AUTOSAR XML (schema 314)
package /ComponentType
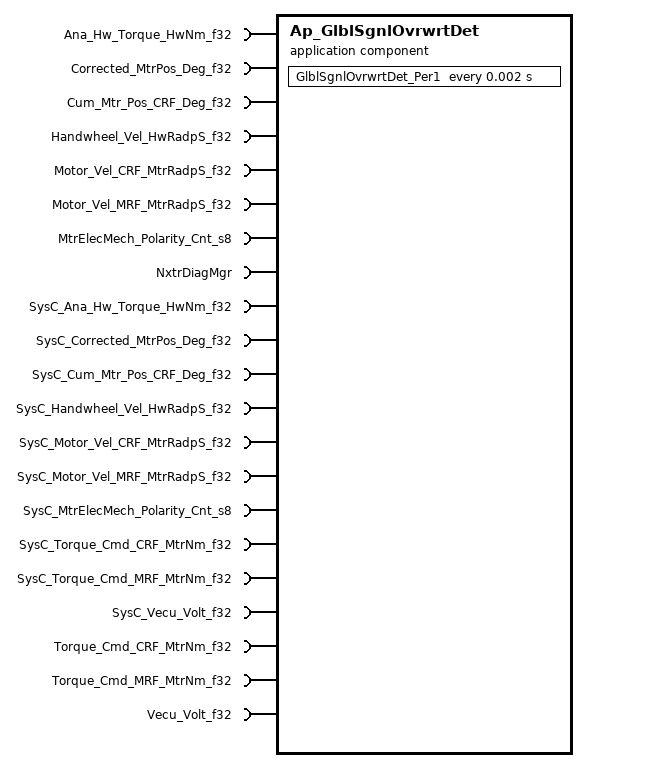
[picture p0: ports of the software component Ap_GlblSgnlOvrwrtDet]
  application software component type Ap_GlblSgnlOvrwrtDet
    21 x require port:
      Ana_Hw_Torque_HwNm_f32: unqueued-receiver-com-spec{data-element=HwNm_f32, init-value=D_ZERO_ULS_F32}, required-interface=Ana_Hw_Torque_HwNm_f32
      Corrected_MtrPos_Deg_f32: unqueued-receiver-com-spec{data-element=Deg_f32, init-value=D_ZERO_ULS_F32}, required-interface=Corrected_MtrPos_Deg_f32
      Cum_Mtr_Pos_CRF_Deg_f32: unqueued-receiver-com-spec{data-element=Deg_f32, init-value=D_ZERO_ULS_F32}, required-interface=Cum_Mtr_Pos_CRF_Deg_f32
      Handwheel_Vel_HwRadpS_f32: unqueued-receiver-com-spec{data-element=HwRadpS_f32, init-value=D_ZERO_ULS_F32}, required-interface=Handwheel_Vel_HwRadpS_f32
      Motor_Vel_CRF_MtrRadpS_f32: unqueued-receiver-com-spec{data-element=MtrRadpS_f32, init-value=D_ZERO_ULS_F32}, required-interface=Motor_Vel_CRF_MtrRadpS_f32
      Motor_Vel_MRF_MtrRadpS_f32: unqueued-receiver-com-spec{data-element=MtrRadpS_f32, init-value=D_ZERO_ULS_F32}, required-interface=Motor_Vel_MRF_MtrRadpS_f32
      MtrElecMech_Polarity_Cnt_s8: unqueued-receiver-com-spec{data-element=Cnt_s8, init-value=D_ZERO_CNT_S8}, required-interface=MtrElecMech_Polarity_Cnt_s8
      NxtrDiagMgr: required-com-specs=[GetNTCFailed, GetNTCStatus, ResetEventStatus, SetNTCStatus, SetOperationCycleState], required-interface=NxtrDiagMgr
      SysC_Ana_Hw_Torque_HwNm_f32: unqueued-receiver-com-spec{data-element=HwNm_f32, init-value=D_ZERO_ULS_F32}, required-interface=SysC_Ana_Hw_Torque_HwNm_f32
      SysC_Corrected_MtrPos_Deg_f32: unqueued-receiver-com-spec{data-element=Deg_f32, init-value=D_ZERO_ULS_F32}, required-interface=SysC_Corrected_MtrPos_Deg_f32
      SysC_Cum_Mtr_Pos_CRF_Deg_f32: unqueued-receiver-com-spec{data-element=Deg_f32, init-value=D_ZERO_ULS_F32}, required-interface=SysC_Cum_Mtr_Pos_CRF_Deg_f32
      SysC_Handwheel_Vel_HwRadpS_f32: unqueued-receiver-com-spec{data-element=HwRadpS_f32, init-value=D_ZERO_ULS_F32}, required-interface=SysC_Handwheel_Vel_HwRadpS_f32
      SysC_Motor_Vel_CRF_MtrRadpS_f32: unqueued-receiver-com-spec{data-element=MtrRadpS_f32, init-value=D_ZERO_ULS_F32}, required-interface=SysC_Motor_Vel_CRF_MtrRadpS_f32
      SysC_Motor_Vel_MRF_MtrRadpS_f32: unqueued-receiver-com-spec{data-element=MtrRadpS_f32, init-value=D_ZERO_ULS_F32}, required-interface=SysC_Motor_Vel_MRF_MtrRadpS_f32
      SysC_MtrElecMech_Polarity_Cnt_s8: unqueued-receiver-com-spec{data-element=Cnt_s8, init-value=D_ZERO_CNT_S8}, required-interface=SysC_MtrElecMech_Polarity_Cnt_s8
      SysC_Torque_Cmd_CRF_MtrNm_f32: unqueued-receiver-com-spec{data-element=MtrNm_f32, init-value=D_ZERO_ULS_F32}, required-interface=SysC_Torque_Cmd_CRF_MtrNm_f32
      SysC_Torque_Cmd_MRF_MtrNm_f32: unqueued-receiver-com-spec{data-element=MtrNm_f32, init-value=D_ZERO_ULS_F32}, required-interface=SysC_Torque_Cmd_MRF_MtrNm_f32
      SysC_Vecu_Volt_f32: unqueued-receiver-com-spec{data-element=Volt_f32, init-value=D_ZERO_ULS_F32}, required-interface=SysC_Vecu_Volt_f32
      Torque_Cmd_CRF_MtrNm_f32: unqueued-receiver-com-spec{data-element=MtrNm_f32, init-value=D_ZERO_ULS_F32}, required-interface=Torque_Cmd_CRF_MtrNm_f32
      Torque_Cmd_MRF_MtrNm_f32: unqueued-receiver-com-spec{data-element=MtrNm_f32, init-value=D_ZERO_ULS_F32}, required-interface=Torque_Cmd_MRF_MtrNm_f32
      Vecu_Volt_f32: unqueued-receiver-com-spec{data-element=Volt_f32, init-value=D_ZERO_ULS_F32}, required-interface=Vecu_Volt_f32
  internal behavior Ap_GlblSgnlOvrwrtDet_InternalBehavior: component=Ap_GlblSgnlOvrwrtDet
    timing event TMT_GlblSgnlOvrwrtDet_Per1: start-on-event=GlblSgnlOvrwrtDet_Per1, period=0.002
    port-api-options:
      enable-take-address=false, indirect-api=false, port=Ana_Hw_Torque_HwNm_f32
      enable-take-address=false, indirect-api=false, port=Corrected_MtrPos_Deg_f32
      enable-take-address=false, indirect-api=false, port=Cum_Mtr_Pos_CRF_Deg_f32
      enable-take-address=false, indirect-api=false, port=Handwheel_Vel_HwRadpS_f32
      enable-take-address=false, indirect-api=false, port=Motor_Vel_CRF_MtrRadpS_f32
      enable-take-address=false, indirect-api=false, port=Motor_Vel_MRF_MtrRadpS_f32
      enable-take-address=false, indirect-api=false, port=MtrElecMech_Polarity_Cnt_s8
      enable-take-address=false, indirect-api=false, port=NxtrDiagMgr
      enable-take-address=false, indirect-api=false, port=SysC_Ana_Hw_Torque_HwNm_f32
      enable-take-address=false, indirect-api=false, port=SysC_Corrected_MtrPos_Deg_f32
      enable-take-address=false, indirect-api=false, port=SysC_Cum_Mtr_Pos_CRF_Deg_f32
      enable-take-address=false, indirect-api=false, port=SysC_Handwheel_Vel_HwRadpS_f32
      enable-take-address=false, indirect-api=false, port=SysC_Motor_Vel_CRF_MtrRadpS_f32
      enable-take-address=false, indirect-api=false, port=SysC_Motor_Vel_MRF_MtrRadpS_f32
      enable-take-address=false, indirect-api=false, port=SysC_MtrElecMech_Polarity_Cnt_s8
      enable-take-address=false, indirect-api=false, port=SysC_Torque_Cmd_CRF_MtrNm_f32
      enable-take-address=false, indirect-api=false, port=SysC_Torque_Cmd_MRF_MtrNm_f32
      enable-take-address=false, indirect-api=false, port=SysC_Vecu_Volt_f32
      enable-take-address=false, indirect-api=false, port=Torque_Cmd_CRF_MtrNm_f32
      enable-take-address=false, indirect-api=false, port=Torque_Cmd_MRF_MtrNm_f32
      enable-take-address=false, indirect-api=false, port=Vecu_Volt_f32
    runnable GlblSgnlOvrwrtDet_Per1
      20 x data read access:
        READ_Ana_Hw_Torque_HwNm_f32_HwNm_f32: data-element=Ana_Hw_Torque_HwNm_f32.HwNm_f32
        READ_Corrected_MtrPos_Deg_f32_Deg_f32: data-element=Corrected_MtrPos_Deg_f32.Deg_f32
        READ_Cum_Mtr_Pos_CRF_Deg_f32_Deg_f32: data-element=Cum_Mtr_Pos_CRF_Deg_f32.Deg_f32
        READ_Handwheel_Vel_HwRadpS_f32_HwRadpS_f32: data-element=Handwheel_Vel_HwRadpS_f32.HwRadpS_f32
        READ_Motor_Vel_CRF_MtrRadpS_f32_MtrRadpS_f32: data-element=Motor_Vel_CRF_MtrRadpS_f32.MtrRadpS_f32
        READ_Motor_Vel_MRF_MtrRadpS_f32_MtrRadpS_f32: data-element=Motor_Vel_MRF_MtrRadpS_f32.MtrRadpS_f32
        READ_MtrElecMech_Polarity_Cnt_s8_Cnt_s8: data-element=MtrElecMech_Polarity_Cnt_s8.Cnt_s8
        READ_SysC_Ana_Hw_Torque_HwNm_f32_HwNm_f32: data-element=SysC_Ana_Hw_Torque_HwNm_f32.HwNm_f32
        READ_SysC_Corrected_MtrPos_Deg_f32_Deg_f32: data-element=SysC_Corrected_MtrPos_Deg_f32.Deg_f32
        READ_SysC_Cum_Mtr_Pos_CRF_Deg_f32_Deg_f32: data-element=SysC_Cum_Mtr_Pos_CRF_Deg_f32.Deg_f32
        READ_SysC_Handwheel_Vel_HwRadpS_f32_HwRadpS_f32: data-element=SysC_Handwheel_Vel_HwRadpS_f32.HwRadpS_f32
        READ_SysC_Motor_Vel_CRF_MtrRadpS_f32_MtrRadpS_f32: data-element=SysC_Motor_Vel_CRF_MtrRadpS_f32.MtrRadpS_f32
        READ_SysC_Motor_Vel_MRF_MtrRadpS_f32_MtrRadpS_f32: data-element=SysC_Motor_Vel_MRF_MtrRadpS_f32.MtrRadpS_f32
        READ_SysC_MtrElecMech_Polarity_Cnt_s8_Cnt_s8: data-element=SysC_MtrElecMech_Polarity_Cnt_s8.Cnt_s8
        READ_SysC_Torque_Cmd_CRF_MtrNm_f32_MtrNm_f32: data-element=SysC_Torque_Cmd_CRF_MtrNm_f32.MtrNm_f32
        READ_SysC_Torque_Cmd_MRF_MtrNm_f32_MtrNm_f32: data-element=SysC_Torque_Cmd_MRF_MtrNm_f32.MtrNm_f32
        READ_SysC_Vecu_Volt_f32_Volt_f32: data-element=SysC_Vecu_Volt_f32.Volt_f32
        READ_Torque_Cmd_CRF_MtrNm_f32_MtrNm_f32: data-element=Torque_Cmd_CRF_MtrNm_f32.MtrNm_f32
        READ_Torque_Cmd_MRF_MtrNm_f32_MtrNm_f32: data-element=Torque_Cmd_MRF_MtrNm_f32.MtrNm_f32
        READ_Vecu_Volt_f32_Volt_f32: data-element=Vecu_Volt_f32.Volt_f32
      sync call SC_NxtrDiagMgr_SetNTCStatus: operation=NxtrDiagMgr.SetNTCStatus, timeout=0
  swc implementation Ap_GlblSgnlOvrwrtDet_Implementation: behavior=Ap_GlblSgnlOvrwrtDet_InternalBehavior
    code-descriptors:
      code Code: type=SRC
